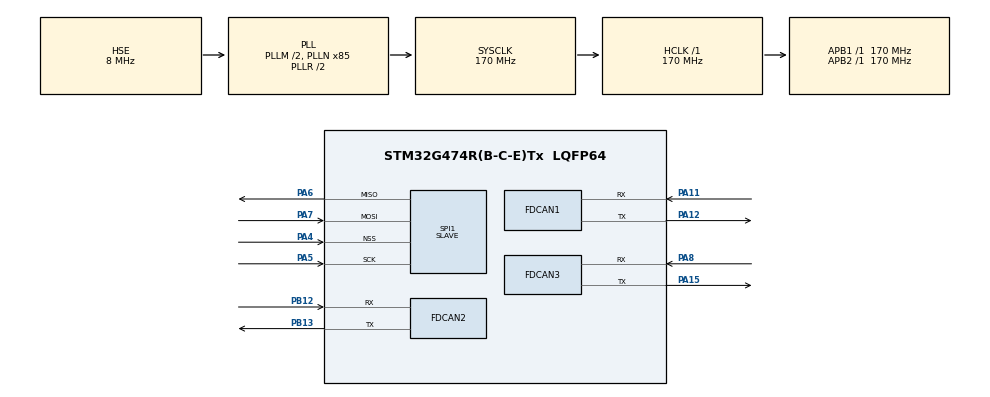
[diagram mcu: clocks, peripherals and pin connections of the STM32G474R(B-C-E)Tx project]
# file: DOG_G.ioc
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Dma.Request0=SPI1_RX
Dma.Request1=SPI1_TX
Dma.SPI1_RX.0.Direction=DMA_PERIPH_TO_MEMORY
Dma.SPI1_RX.0.EventEnable=DISABLE
Dma.SPI1_RX.0.Instance=DMA1_Channel1
Dma.SPI1_RX.0.MemDataAlignment=DMA_MDATAALIGN_BYTE
Dma.SPI1_RX.0.MemInc=DMA_MINC_ENABLE
Dma.SPI1_RX.0.Mode=DMA_NORMAL
Dma.SPI1_RX.0.PeriphDataAlignment=DMA_PDATAALIGN_BYTE
Dma.SPI1_RX.0.PeriphInc=DMA_PINC_DISABLE
Dma.SPI1_RX.0.Polarity=HAL_DMAMUX_REQ_GEN_RISING
Dma.SPI1_RX.0.Priority=DMA_PRIORITY_VERY_HIGH
Dma.SPI1_RX.0.RequestNumber=1
Dma.SPI1_RX.0.SignalID=NONE
Dma.SPI1_RX.0.SyncEnable=DISABLE
Dma.SPI1_RX.0.SyncPolarity=HAL_DMAMUX_SYNC_NO_EVENT
Dma.SPI1_RX.0.SyncRequestNumber=1
Dma.SPI1_RX.0.SyncSignalID=NONE
Dma.SPI1_TX.1.Direction=DMA_MEMORY_TO_PERIPH
Dma.SPI1_TX.1.EventEnable=DISABLE
Dma.SPI1_TX.1.Instance=DMA1_Channel2
Dma.SPI1_TX.1.MemDataAlignment=DMA_MDATAALIGN_BYTE
Dma.SPI1_TX.1.MemInc=DMA_MINC_ENABLE
Dma.SPI1_TX.1.Mode=DMA_NORMAL
Dma.SPI1_TX.1.PeriphDataAlignment=DMA_PDATAALIGN_BYTE
Dma.SPI1_TX.1.PeriphInc=DMA_PINC_DISABLE
Dma.SPI1_TX.1.Polarity=HAL_DMAMUX_REQ_GEN_RISING
Dma.SPI1_TX.1.Priority=DMA_PRIORITY_VERY_HIGH
Dma.SPI1_TX.1.RequestNumber=1
Dma.SPI1_TX.1.SignalID=NONE
Dma.SPI1_TX.1.SyncEnable=DISABLE
Dma.SPI1_TX.1.SyncPolarity=HAL_DMAMUX_SYNC_NO_EVENT
Dma.SPI1_TX.1.SyncRequestNumber=1
Dma.SPI1_TX.1.SyncSignalID=NONE
FDCAN1.AutoRetransmission=ENABLE
FDCAN1.CalculateBaudRateNominal=999999
FDCAN1.CalculateTimeBitNominal=1000
FDCAN1.CalculateTimeQuantumNominal=58.82352941176471
FDCAN1.ExtFiltersNbr=0
FDCAN1.NominalPrescaler=10
FDCAN1.NominalSyncJumpWidth=4
FDCAN1.NominalTimeSeg1=12
FDCAN1.NominalTimeSeg2=4
FDCAN1.StdFiltersNbr=1
FDCAN1.TxFifoQueueMode=FDCAN_TX_FIFO_OPERATION
FDCAN2.CalculateBaudRateNominal=999999
FDCAN2.CalculateTimeBitNominal=1000
FDCAN2.CalculateTimeQuantumNominal=58.82352941176471
FDCAN2.DataSyncJumpWidth=1
FDCAN2.NominalPrescaler=10
FDCAN2.NominalSyncJumpWidth=4
FDCAN2.NominalTimeSeg1=12
FDCAN2.NominalTimeSeg2=4
FDCAN2.StdFiltersNbr=1
FDCAN3.CalculateBaudRateNominal=999999
FDCAN3.CalculateTimeBitNominal=1000
FDCAN3.CalculateTimeQuantumNominal=58.82352941176471
FDCAN3.DataSyncJumpWidth=1
FDCAN3.NominalPrescaler=10
FDCAN3.NominalSyncJumpWidth=4
FDCAN3.NominalTimeSeg1=12
FDCAN3.NominalTimeSeg2=4
FDCAN3.StdFiltersNbr=1
Mcu.Family=STM32G4
Mcu.Name=STM32G474R(B-C-E)Tx
Mcu.Package=LQFP64
NVIC.DMA1_Channel1_IRQn=true\:0\:0\:true\:false\:true\:false\:true\:true
NVIC.DMA1_Channel2_IRQn=true\:0\:0\:true\:false\:true\:false\:true\:true
NVIC.FDCAN1_IT0_IRQn=true\:1\:0\:true\:false\:true\:true\:true\:true
NVIC.FDCAN1_IT1_IRQn=true\:1\:0\:true\:false\:true\:true\:true\:true
NVIC.FDCAN2_IT0_IRQn=true\:1\:0\:true\:false\:true\:true\:true\:true
NVIC.FDCAN2_IT1_IRQn=true\:1\:0\:true\:false\:true\:true\:true\:true
NVIC.FDCAN3_IT0_IRQn=true\:1\:0\:true\:false\:true\:true\:true\:true
NVIC.FDCAN3_IT1_IRQn=true\:1\:0\:true\:false\:true\:true\:true\:true
NVIC.FPU_IRQn=true\:0\:0\:false\:false\:true\:true\:false\:true
NVIC.PriorityGroup=NVIC_PRIORITYGROUP_4
NVIC.SPI1_IRQn=true\:0\:0\:false\:false\:true\:true\:true\:true
PA11.GPIO_Speed=GPIO_SPEED_FREQ_VERY_HIGH
PA11.Mode=FDCAN_Activate
PA11.Signal=FDCAN1_RX
PA12.GPIO_Speed=GPIO_SPEED_FREQ_VERY_HIGH
PA12.Mode=FDCAN_Activate
PA12.Signal=FDCAN1_TX
PA13.Mode=Serial_Wire
PA13.Signal=SYS_JTMS-SWDIO
PA14.Mode=Serial_Wire
PA14.Signal=SYS_JTCK-SWCLK
PA15.GPIO_Speed=GPIO_SPEED_FREQ_VERY_HIGH
PA15.Mode=FDCAN_Activate
PA15.Signal=FDCAN3_TX
PA4.GPIO_PuPd=GPIO_PULLUP
PA4.GPIO_Speed=GPIO_SPEED_FREQ_VERY_HIGH
PA4.Mode=NSS_Signal_Hard_Input
PA4.Signal=SPI1_NSS
PA5.GPIO_PuPd=GPIO_PULLUP
PA5.GPIO_Speed=GPIO_SPEED_FREQ_VERY_HIGH
PA5.Mode=Full_Duplex_Slave
PA5.Signal=SPI1_SCK
PA6.GPIO_PuPd=GPIO_PULLUP
PA6.GPIO_Speed=GPIO_SPEED_FREQ_VERY_HIGH
PA6.Mode=Full_Duplex_Slave
PA6.Signal=SPI1_MISO
PA7.GPIO_PuPd=GPIO_PULLUP
PA7.GPIO_Speed=GPIO_SPEED_FREQ_VERY_HIGH
PA7.Mode=Full_Duplex_Slave
PA7.Signal=SPI1_MOSI
PA8.GPIO_Speed=GPIO_SPEED_FREQ_VERY_HIGH
PA8.Mode=FDCAN_Activate
PA8.Signal=FDCAN3_RX
PB12.GPIO_Speed=GPIO_SPEED_FREQ_VERY_HIGH
PB12.Mode=FDCAN_Activate
PB12.Signal=FDCAN2_RX
PB13.GPIO_Speed=GPIO_SPEED_FREQ_VERY_HIGH
PB13.Mode=FDCAN_Activate
PB13.Signal=FDCAN2_TX
PF0-OSC_IN.Mode=HSE-External-Oscillator
PF0-OSC_IN.Signal=RCC_OSC_IN
PF1-OSC_OUT.Mode=HSE-External-Oscillator
PF1-OSC_OUT.Signal=RCC_OSC_OUT
ProjectManager.HeapSize=0x200
ProjectManager.StackSize=0x400
ProjectManager.TargetToolchain=MDK-ARM V5.32
RCC.ADC12Freq_Value=170000000
RCC.ADC345Freq_Value=170000000
RCC.AHBFreq_Value=170000000
RCC.APB1Freq_Value=170000000
RCC.APB1TimFreq_Value=170000000
RCC.APB2Freq_Value=170000000
RCC.APB2TimFreq_Value=170000000
RCC.CortexFreq_Value=170000000
RCC.EXTERNAL_CLOCK_VALUE=12288000
RCC.FDCANCLockSelection=RCC_FDCANCLKSOURCE_PLL
RCC.HCLKFreq_Value=170000000
RCC.HSE_VALUE=8000000
RCC.HSI48_VALUE=48000000
RCC.HSI_VALUE=16000000
RCC.LSE_VALUE=32768
RCC.PLLM=RCC_PLLM_DIV2
RCC.PLLN=85
RCC.PLLSourceVirtual=RCC_PLLSOURCE_HSE
RCC.SYSCLKFreq_VALUE=170000000
RCC.SYSCLKSource=RCC_SYSCLKSOURCE_PLLCLK
RCC.USBFreq_Value=170000000
RCC.VCOOutputFreq_Value=340000000
SPI1.CLKPhase=SPI_PHASE_1EDGE
SPI1.CLKPolarity=SPI_POLARITY_LOW
SPI1.DataSize=SPI_DATASIZE_8BIT
SPI1.Direction=SPI_DIRECTION_2LINES
SPI1.Mode=SPI_MODE_SLAVE
SPI1.VirtualNSS=VM_NSSHARD
SPI1.VirtualType=VM_SLAVE
VP_SYS_VS_DBSignals.Mode=DisableDeadBatterySignals
board=custom

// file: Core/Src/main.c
/* USER CODE BEGIN Header */
/**
  ******************************************************************************
  * @file           : main.c
  * @brief          : Main program body
  ******************************************************************************
  * @attention
  *
  * Copyright (c) 2026 STMicroelectronics.
  * All rights reserved.
  *
  * This software is licensed under terms that can be found in the LICENSE file
  * in the root directory of this software component.
  * If no LICENSE file comes with this software, it is provided AS-IS.
  *
  ******************************************************************************
  */
/* USER CODE END Header */
#include "main.h"
#include "dma.h"
#include "fdcan.h"
#include "spi.h"
#include "gpio.h"

/* USER CODE BEGIN Includes */
#include "slave_controller.h"
/* USER CODE END Includes */

void SystemClock_Config(void);

int main(void)
{

  /* MCU Configuration--------------------------------------------------------*/

  /* Reset of all peripherals, Initializes the Flash interface and the Systick. */
  HAL_Init();

  /* Configure the system clock */
  SystemClock_Config();

  /* Initialize all configured peripherals */
  MX_GPIO_Init();
  MX_DMA_Init();
  MX_FDCAN1_Init();
  MX_FDCAN2_Init();
  MX_FDCAN3_Init();
  MX_SPI1_Init();
  /* USER CODE BEGIN 2 */
  // 初始化从控制器
  SlaveController_Init();
  /* USER CODE END 2 */

  /* Infinite loop */
  while (1)
  {

    /* USER CODE BEGIN 3 */
    // 从控制器主循环处理
    SlaveController_Process();
  }
  /* USER CODE END 3 */
}

void SystemClock_Config(void)
{
  RCC_OscInitTypeDef RCC_OscInitStruct = {0};
  RCC_ClkInitTypeDef RCC_ClkInitStruct = {0};

  /** Configure the main internal regulator output voltage
  */
  HAL_PWREx_ControlVoltageScaling(PWR_REGULATOR_VOLTAGE_SCALE1_BOOST);

  /** Initializes the RCC Oscillators according to the specified parameters
  * in the RCC_OscInitTypeDef structure.
  */
  RCC_OscInitStruct.OscillatorType = RCC_OSCILLATORTYPE_HSE;
  RCC_OscInitStruct.HSEState = RCC_HSE_ON;
  RCC_OscInitStruct.PLL.PLLState = RCC_PLL_ON;
  RCC_OscInitStruct.PLL.PLLSource = RCC_PLLSOURCE_HSE;
  RCC_OscInitStruct.PLL.PLLM = RCC_PLLM_DIV2;
  RCC_OscInitStruct.PLL.PLLN = 85;
  RCC_OscInitStruct.PLL.PLLP = RCC_PLLP_DIV2;
  RCC_OscInitStruct.PLL.PLLQ = RCC_PLLQ_DIV2;
  RCC_OscInitStruct.PLL.PLLR = RCC_PLLR_DIV2;
  if (HAL_RCC_OscConfig(&RCC_OscInitStruct) != HAL_OK)
  {
    Error_Handler();
  }

  /** Initializes the CPU, AHB and APB buses clocks
  */
  RCC_ClkInitStruct.ClockType = RCC_CLOCKTYPE_HCLK|RCC_CLOCKTYPE_SYSCLK
                              |RCC_CLOCKTYPE_PCLK1|RCC_CLOCKTYPE_PCLK2;
  RCC_ClkInitStruct.SYSCLKSource = RCC_SYSCLKSOURCE_PLLCLK;
  RCC_ClkInitStruct.AHBCLKDivider = RCC_SYSCLK_DIV1;
  RCC_ClkInitStruct.APB1CLKDivider = RCC_HCLK_DIV1;
  RCC_ClkInitStruct.APB2CLKDivider = RCC_HCLK_DIV1;

  if (HAL_RCC_ClockConfig(&RCC_ClkInitStruct, FLASH_LATENCY_4) != HAL_OK)
  {
    Error_Handler();
  }
}

void Error_Handler(void)
{
  __disable_irq();
  while (1)
  {
  }
}
